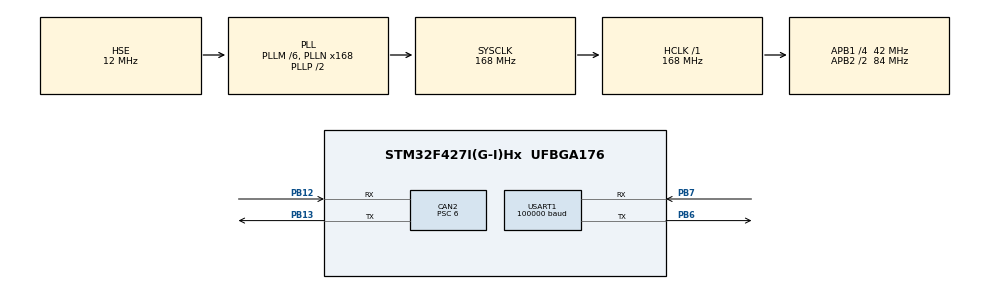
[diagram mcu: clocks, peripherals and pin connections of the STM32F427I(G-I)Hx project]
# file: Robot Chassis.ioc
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CAN2.BS1=CAN_BS1_4TQ
CAN2.BS2=CAN_BS2_2TQ
CAN2.CalculateTimeQuantum=142.85714285714286
CAN2.Prescaler=6
Dma.Request0=USART1_RX
Dma.USART1_RX.0.Direction=DMA_PERIPH_TO_MEMORY
Dma.USART1_RX.0.FIFOMode=DMA_FIFOMODE_DISABLE
Dma.USART1_RX.0.Instance=DMA2_Stream2
Dma.USART1_RX.0.MemDataAlignment=DMA_MDATAALIGN_BYTE
Dma.USART1_RX.0.MemInc=DMA_MINC_ENABLE
Dma.USART1_RX.0.Mode=DMA_NORMAL
Dma.USART1_RX.0.PeriphDataAlignment=DMA_PDATAALIGN_BYTE
Dma.USART1_RX.0.PeriphInc=DMA_PINC_DISABLE
Dma.USART1_RX.0.Priority=DMA_PRIORITY_LOW
Mcu.Family=STM32F4
Mcu.Name=STM32F427I(G-I)Hx
Mcu.Package=UFBGA176
NVIC.CAN2_RX0_IRQn=true\:0\:0\:false\:false\:true\:true\:true
NVIC.DMA2_Stream2_IRQn=true\:0\:0\:false\:false\:true\:false\:true
NVIC.PriorityGroup=NVIC_PRIORITYGROUP_4
NVIC.USART1_IRQn=true\:0\:0\:false\:false\:true\:true\:true
PB12.Mode=Slave
PB12.Signal=CAN2_RX
PB13.Mode=Slave
PB13.Signal=CAN2_TX
PB6.Mode=Asynchronous
PB6.Signal=USART1_TX
PB7.Mode=Asynchronous
PB7.Signal=USART1_RX
PH0/OSC_IN.Mode=HSE-External-Oscillator
PH0/OSC_IN.Signal=RCC_OSC_IN
PH1/OSC_OUT.Mode=HSE-External-Oscillator
PH1/OSC_OUT.Signal=RCC_OSC_OUT
ProjectManager.HeapSize=0x200
ProjectManager.StackSize=0x400
ProjectManager.TargetToolchain=MDK-ARM V5
RCC.48MHZClocksFreq_Value=84000000
RCC.AHBFreq_Value=168000000
RCC.APB1CLKDivider=RCC_HCLK_DIV4
RCC.APB1Freq_Value=42000000
RCC.APB1TimFreq_Value=84000000
RCC.APB2CLKDivider=RCC_HCLK_DIV2
RCC.APB2Freq_Value=84000000
RCC.APB2TimFreq_Value=168000000
RCC.CortexFreq_Value=168000000
RCC.HCLKFreq_Value=168000000
RCC.HSE_VALUE=12000000
RCC.HSI_VALUE=16000000
RCC.LSE_VALUE=32768
RCC.PLLM=6
RCC.PLLN=168
RCC.PLLSourceVirtual=RCC_PLLSOURCE_HSE
RCC.SYSCLKFreq_VALUE=168000000
RCC.SYSCLKSource=RCC_SYSCLKSOURCE_PLLCLK
RCC.VCOOutputFreq_Value=336000000
USART1.BaudRate=100000
USART1.Parity=PARITY_EVEN
USART1.VirtualMode=VM_ASYNC
board=custom

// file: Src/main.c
/* USER CODE BEGIN Header */
/**
  ******************************************************************************
  * @file           : main.c
  * @brief          : Main program body
  ******************************************************************************
  * @attention
  *
  * <h2><center>&copy; Copyright (c) 2020 STMicroelectronics.
  * All rights reserved.</center></h2>
  *
  * This software component is licensed by ST under BSD 3-Clause license,
  * the "License"; You may not use this file except in compliance with the
  * License. You may obtain a copy of the License at:
  *                        opensource.org/licenses/BSD-3-Clause
  *
  ******************************************************************************
  */
/* USER CODE END Header */

#include "main.h"
#include "can.h"
#include "dma.h"
#include "usart.h"
#include "gpio.h"

/* USER CODE BEGIN Includes */
#include "get_motor.h"
#include "pid.h"

/* USER CODE END Includes */

void SystemClock_Config(void);

int main(void)
{

  /* MCU Configuration--------------------------------------------------------*/

  /* Reset of all peripherals, Initializes the Flash interface and the Systick. */
  HAL_Init();

  /* Configure the system clock */
  SystemClock_Config();

  /* Initialize all configured peripherals */
  MX_GPIO_Init();
  MX_DMA_Init();
  MX_CAN2_Init();
  MX_USART1_UART_Init();
  /* USER CODE BEGIN 2 */
	__HAL_UART_ENABLE_IT(&huart1,UART_IT_IDLE);
	HAL_UART_Receive_DMA(&huart1,	mybuffer,18);
	CANfilterConf(&hcan2);
	HAL_CAN_ActivateNotification(&hcan2,CAN_IT_RX_FIFO0_MSG_PENDING);
	HAL_CAN_Start(&hcan2);
	Chassis_pid_init();
  /* USER CODE END 2 */

  /* Infinite loop */
  /* USER CODE BEGIN WHILE */
  while (1)
  {
		//延时可能有问题，将解码函数放在while循环里面保证数据实时性
    /* USER CODE END WHILE */
//		pid_calc(&pid_3508_remote_spd[0],motor1.speed_rpm,500);
//		Send_message(pid_3508_remote_spd[0].pos_out,0,0,0);
//		HAL_Delay(5);
		dipan_speed();
		if(RC_CtrlData.rc.s1==2)
		{
			pid_calc(&pid_3508_remote_spd[0],motor1.speed_rpm,wheel[0]);
			pid_calc(&pid_3508_remote_spd[1],motor2.speed_rpm,wheel[1]);
			pid_calc(&pid_3508_remote_spd[2],motor3.speed_rpm,wheel[2]);
			pid_calc(&pid_3508_remote_spd[3],motor4.speed_rpm,wheel[3]);

			Send_message(pid_3508_remote_spd[0].pos_out,pid_3508_remote_spd[1].pos_out,pid_3508_remote_spd[2].pos_out,pid_3508_remote_spd[3].pos_out);
			HAL_Delay(5);
		}
  }
}

void SystemClock_Config(void)
{
  RCC_OscInitTypeDef RCC_OscInitStruct = {0};
  RCC_ClkInitTypeDef RCC_ClkInitStruct = {0};

  /** Configure the main internal regulator output voltage
  */
  __HAL_RCC_PWR_CLK_ENABLE();
  __HAL_PWR_VOLTAGESCALING_CONFIG(PWR_REGULATOR_VOLTAGE_SCALE1);
  /** Initializes the CPU, AHB and APB busses clocks
  */
  RCC_OscInitStruct.OscillatorType = RCC_OSCILLATORTYPE_HSE;
  RCC_OscInitStruct.HSEState = RCC_HSE_ON;
  RCC_OscInitStruct.PLL.PLLState = RCC_PLL_ON;
  RCC_OscInitStruct.PLL.PLLSource = RCC_PLLSOURCE_HSE;
  RCC_OscInitStruct.PLL.PLLM = 6;
  RCC_OscInitStruct.PLL.PLLN = 168;
  RCC_OscInitStruct.PLL.PLLP = RCC_PLLP_DIV2;
  RCC_OscInitStruct.PLL.PLLQ = 4;
  if (HAL_RCC_OscConfig(&RCC_OscInitStruct) != HAL_OK)
  {
    Error_Handler();
  }
  /** Initializes the CPU, AHB and APB busses clocks
  */
  RCC_ClkInitStruct.ClockType = RCC_CLOCKTYPE_HCLK|RCC_CLOCKTYPE_SYSCLK
                              |RCC_CLOCKTYPE_PCLK1|RCC_CLOCKTYPE_PCLK2;
  RCC_ClkInitStruct.SYSCLKSource = RCC_SYSCLKSOURCE_PLLCLK;
  RCC_ClkInitStruct.AHBCLKDivider = RCC_SYSCLK_DIV1;
  RCC_ClkInitStruct.APB1CLKDivider = RCC_HCLK_DIV4;
  RCC_ClkInitStruct.APB2CLKDivider = RCC_HCLK_DIV2;

  if (HAL_RCC_ClockConfig(&RCC_ClkInitStruct, FLASH_LATENCY_5) != HAL_OK)
  {
    Error_Handler();
  }
}

void Error_Handler(void)
{
}

/************************ (C) COPYRIGHT STMicroelectronics *****END OF FILE****/
